AUTOSAR XML (schema 4-0-3)
package /ComponentTypes
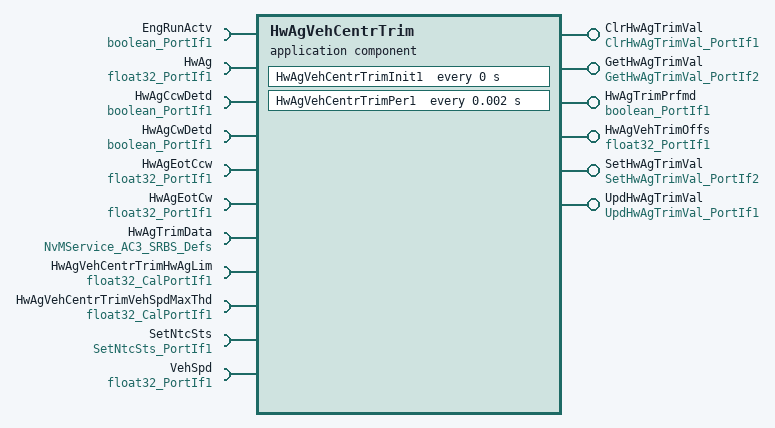
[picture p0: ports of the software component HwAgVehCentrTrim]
  application sw component type HwAgVehCentrTrim
    6 x provide port:
      ClrHwAgTrimVal: server-com-spec{operation=Oper, queue-length=1}, provided-interface=ClrHwAgTrimVal_PortIf1
      GetHwAgTrimVal: server-com-spec{operation=Oper, queue-length=1}, provided-interface=GetHwAgTrimVal_PortIf2
      HwAgTrimPrfmd: nonqueued-sender-com-spec{data-element=Logl, init-value=0}, provided-interface=boolean_PortIf1
      HwAgVehTrimOffs: nonqueued-sender-com-spec{data-element=Val, init-value=0}, provided-interface=float32_PortIf1
      SetHwAgTrimVal: server-com-spec{operation=Oper, queue-length=1}, provided-interface=SetHwAgTrimVal_PortIf2
      UpdHwAgTrimVal: server-com-spec{operation=Oper, queue-length=1}, provided-interface=UpdHwAgTrimVal_PortIf1
    11 x require port:
      EngRunActv: nonqueued-receiver-com-spec{data-element=Logl, filter=data-filter-type=ALWAYS, init-value=0}, required-interface=boolean_PortIf1
      HwAg: nonqueued-receiver-com-spec{data-element=Val, filter=data-filter-type=ALWAYS, init-value=0}, required-interface=float32_PortIf1
      HwAgCcwDetd: nonqueued-receiver-com-spec{data-element=Logl, filter=data-filter-type=ALWAYS, init-value=0}, required-interface=boolean_PortIf1
      HwAgCwDetd: nonqueued-receiver-com-spec{data-element=Logl, filter=data-filter-type=ALWAYS, init-value=0}, required-interface=boolean_PortIf1
      HwAgEotCcw: nonqueued-receiver-com-spec{data-element=Val, filter=data-filter-type=ALWAYS, init-value=-360}, required-interface=float32_PortIf1
      HwAgEotCw: nonqueued-receiver-com-spec{data-element=Val, filter=data-filter-type=ALWAYS, init-value=360}, required-interface=float32_PortIf1
      HwAgTrimData: required-interface=NvMService_AC3_SRBS_Defs
      HwAgVehCentrTrimHwAgLim: parameter-require-com-spec{init-value=30, parameter=Val}, required-interface=float32_CalPortIf1
      HwAgVehCentrTrimVehSpdMaxThd: parameter-require-com-spec{init-value=0, parameter=Val}, required-interface=float32_CalPortIf1
      SetNtcSts: required-interface=SetNtcSts_PortIf1
      VehSpd: nonqueued-receiver-com-spec{data-element=Val, filter=data-filter-type=ALWAYS, init-value=0}, required-interface=float32_PortIf1
    behavior HwAgVehCentrTrim_InternalBehavior
      ar-typed-per-instance-memorys:
        data HwAgTrimData: sw-calibration-access=READ-ONLY, type=HwAgSnsrTrimRec1
      operation invoked event OIT_ClrHwAgTrimVal_Oper_ClrHwAgTrimVal_Oper: start-on-event=ClrHwAgTrimVal_Oper, operation=ClrHwAgTrimVal.Oper
      operation invoked event OIT_GetHwAgTrimVal_Oper_GetHwAgTrimVal_Oper: start-on-event=GetHwAgTrimVal_Oper, operation=GetHwAgTrimVal.Oper
      timing event HwAgVehCentrTrim_InitEvent: start-on-event=HwAgVehCentrTrimInit1, period=0
      timing event TMT_HwAgVehCentrTrimPer1: start-on-event=HwAgVehCentrTrimPer1, period=0.002
      operation invoked event OIT_SetHwAgTrimVal_Oper_SetHwAgTrimVal_Oper: start-on-event=SetHwAgTrimVal_Oper, operation=SetHwAgTrimVal.Oper
      operation invoked event OIT_UpdHwAgTrimVal_Oper_UpdHwAgTrimVal_Oper: start-on-event=UpdHwAgTrimVal_Oper, operation=UpdHwAgTrimVal.Oper
      6 x runnable:
        ClrHwAgTrimVal_Oper: can-be-invoked-concurrently=true
          sync call SC_HwAgTrimVal_SetRamBlockStatus: operation=HwAgTrimData.SetRamBlockStatus, timeout=0
          sync call SC_SetNtcSts_Oper: operation=SetNtcSts.Oper, timeout=0
        GetHwAgTrimVal_Oper
        HwAgVehCentrTrimInit1
        HwAgVehCentrTrimPer1
          data-receive-point-by-arguments:
            access REC_HwAg_Val: accessed-variable=HwAg.Val
          data-send-points:
            access SEND_HwAgTrimPrfmd_Logl: accessed-variable=HwAgTrimPrfmd.Logl
            access SEND_HwAgVehTrimOffs_Val: accessed-variable=HwAgVehTrimOffs.Val
          sync call SC_HwAgTrimVal_SetRamBlockStatus: operation=HwAgTrimData.SetRamBlockStatus, timeout=0
          sync call SC_SetNtcSts_Oper: operation=SetNtcSts.Oper, timeout=0
        SetHwAgTrimVal_Oper
          sync call SC_HwAgTrimData_SetRamBlockStatus: operation=HwAgTrimData.SetRamBlockStatus, timeout=0
        UpdHwAgTrimVal_Oper: can-be-invoked-concurrently=true
          data-receive-point-by-arguments:
            7 x access:
              REC_EngRunActv_Logl: accessed-variable=EngRunActv.Logl
              REC_HwAg_Val: accessed-variable=HwAg.Val
              REC_HwAgEotCcw_Val: accessed-variable=HwAgEotCcw.Val
              REC_HwAgEotCcwDetd_Logl: accessed-variable=HwAgCcwDetd.Logl
              REC_HwAgEotCw_Val: accessed-variable=HwAgEotCw.Val
              REC_HwAgEotCwDetd_Logl: accessed-variable=HwAgCwDetd.Logl
              REC_VehSpd_Val: accessed-variable=VehSpd.Val
          data-send-points:
            access SEND_HwAgTrimPrfmd_Logl: accessed-variable=HwAgTrimPrfmd.Logl
          sync call SC_HwAgTrimVal_SetRamBlockStatus: operation=HwAgTrimData.SetRamBlockStatus, timeout=0
          sync call SC_SetNtcSts_Oper: operation=SetNtcSts.Oper, timeout=0
      swc service dependency NvmHwAgTrimData
        assigned-datas:
          role=ramBlock, used-data-element=HwAgTrimData
          role=defaultValue, used-parameter-element=HwAgTrimDataDft
        assigned-ports:
          port-prototype=HwAgTrimData, role=NvMService_AC3_SRBS_Defs
          port-prototype=HwAgTrimData, role=NvMService_AC3_SRBS_Defs
        service-needs:
          nv block needs NvmHwAgTrimData: n-data-sets=0, readonly=false, reliability=ERROR-DETECTION, resistant-to-changed-sw=true, restore-at-start=true, store-at-shutdown=true, write-only-once=false, writing-frequency=0, writing-priority=LOW
      shared-parameters:
        parameter data prototype HwAgTrimDataDft: sw-calibration-access=READ-WRITE, type=HwAgSnsrTrimRec1, init-value=fields=[ElementConstant:0, ElementConstant:0]
  swc implementation HwAgVehCentrTrim_Implementation: behavior=HwAgVehCentrTrim_InternalBehavior
    code-descriptors:
      code Default: artifact-descriptors=autosar-engineering-object={short-label=Default, category=SWSRC}
